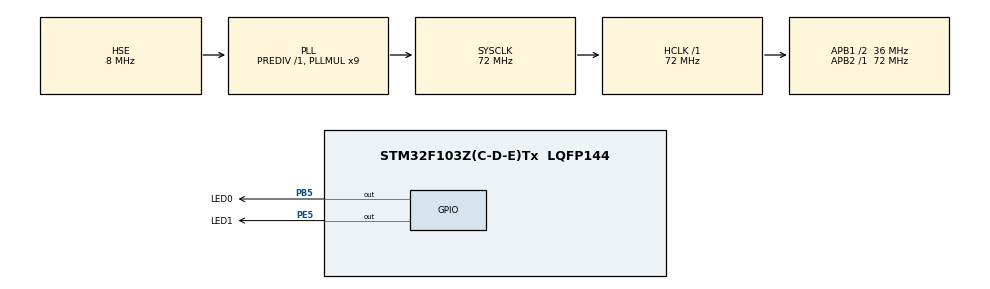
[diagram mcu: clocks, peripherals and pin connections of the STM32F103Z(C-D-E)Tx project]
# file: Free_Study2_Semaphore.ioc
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FREERTOS.BinarySemaphores01=bSem01,Dynamic,NULL
FREERTOS.CountingSemaphores01=cSem01,10,Dynamic,NULL
FREERTOS.Tasks01=Periodic,0,128,PeriodicTask,Default,NULL,Dynamic,NULL,NULL;Handle,0,128,HandleTask,Default,NULL,Dynamic,NULL,NULL;SemGen,0,128,SemGenTask,Default,NULL,Dynamic,NULL,NULL
FREERTOS.configUSE_COUNTING_SEMAPHORES=1
Mcu.Family=STM32F1
Mcu.Name=STM32F103Z(C-D-E)Tx
Mcu.Package=LQFP144
NVIC.PriorityGroup=NVIC_PRIORITYGROUP_4
NVIC.TIM4_IRQn=true\:0\:0\:false\:false\:true\:false\:false\:true
NVIC.TimeBase=TIM4_IRQn
NVIC.TimeBaseIP=TIM4
OSC_IN.Mode=HSE-External-Oscillator
OSC_IN.Signal=RCC_OSC_IN
OSC_OUT.Mode=HSE-External-Oscillator
OSC_OUT.Signal=RCC_OSC_OUT
PA13.Mode=Serial_Wire
PA13.Signal=SYS_JTMS-SWDIO
PA14.Mode=Serial_Wire
PA14.Signal=SYS_JTCK-SWCLK
PB5.GPIO_Label=LED0
PB5.Signal=GPIO_Output
PE5.GPIO_Label=LED1
PE5.Signal=GPIO_Output
ProjectManager.HeapSize=0x200
ProjectManager.StackSize=0x400
ProjectManager.TargetToolchain=STM32CubeIDE
RCC.AHBFreq_Value=72000000
RCC.APB1CLKDivider=RCC_HCLK_DIV2
RCC.APB1Freq_Value=36000000
RCC.APB1TimFreq_Value=72000000
RCC.APB2Freq_Value=72000000
RCC.APB2TimFreq_Value=72000000
RCC.HCLKFreq_Value=72000000
RCC.PLLMUL=RCC_PLL_MUL9
RCC.PLLSourceVirtual=RCC_PLLSOURCE_HSE
RCC.SYSCLKFreq_VALUE=72000000
RCC.SYSCLKSource=RCC_SYSCLKSOURCE_PLLCLK
RCC.USBFreq_Value=72000000
VP_FREERTOS_VS_CMSIS_V1.Mode=CMSIS_V1
VP_SYS_VS_tim4.Mode=TIM4
board=custom

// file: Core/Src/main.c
/* USER CODE BEGIN Header */
/**
 ******************************************************************************
 * @file           : main.c
 * @brief          : Main program body
 ******************************************************************************
 * @attention
 *
 * <h2><center>&copy; Copyright (c) 2020 STMicroelectronics.
 * All rights reserved.</center></h2>
 *
 * This software component is licensed by ST under BSD 3-Clause license,
 * the "License"; You may not use this file except in compliance with the
 * License. You may obtain a copy of the License at:
 *                        opensource.org/licenses/BSD-3-Clause
 *
 ******************************************************************************
 */
/* USER CODE END Header */
#include "main.h"
#include "cmsis_os.h"

osThreadId PeriodicHandle;
osThreadId HandleHandle;
osThreadId SemGenHandle;
osSemaphoreId bSem01Handle;
osSemaphoreId cSem01Handle;

void SystemClock_Config(void);
static void MX_GPIO_Init(void);
void PeriodicTask(const void *argument);
void HandleTask(const void *argument);
void SemGenTask(const void *argument);

int main(void)
{

	/* MCU Configuration--------------------------------------------------------*/

	/* Reset of all peripherals, Initializes the Flash interface and the Systick. */
	HAL_Init();

	/* Configure the system clock */
	SystemClock_Config();

	/* Initialize all configured peripherals */
	MX_GPIO_Init();

	/* Create the semaphores(s) */
	/* definition and creation of bSem01 */
	osSemaphoreDef(bSem01);
	bSem01Handle = osSemaphoreCreate(osSemaphore(bSem01), 1);

	/* definition and creation of cSem01 */
	osSemaphoreDef(cSem01);
	cSem01Handle = osSemaphoreCreate(osSemaphore(cSem01), 10);

	/* Create the thread(s) */
	/* definition and creation of Periodic */
	osThreadDef(Periodic, PeriodicTask, osPriorityNormal, 0, 128);
	PeriodicHandle = osThreadCreate(osThread(Periodic), NULL);

	/* definition and creation of Handle */
	osThreadDef(Handle, HandleTask, osPriorityNormal, 0, 128);
	HandleHandle = osThreadCreate(osThread(Handle), NULL);

	/* definition and creation of SemGen */
	osThreadDef(SemGen, SemGenTask, osPriorityNormal, 0, 128);
	SemGenHandle = osThreadCreate(osThread(SemGen), NULL);

	/* Start scheduler */
	osKernelStart();

	/* We should never get here as control is now taken by the scheduler */
	/* Infinite loop */
	while (1)
	{

	}
}

void SystemClock_Config(void)
{
	RCC_OscInitTypeDef RCC_OscInitStruct =
	{ 0 };
	RCC_ClkInitTypeDef RCC_ClkInitStruct =
	{ 0 };

	/** Initializes the RCC Oscillators according to the specified parameters
	 * in the RCC_OscInitTypeDef structure.
	 */
	RCC_OscInitStruct.OscillatorType = RCC_OSCILLATORTYPE_HSE;
	RCC_OscInitStruct.HSEState = RCC_HSE_ON;
	RCC_OscInitStruct.HSEPredivValue = RCC_HSE_PREDIV_DIV1;
	RCC_OscInitStruct.HSIState = RCC_HSI_ON;
	RCC_OscInitStruct.PLL.PLLState = RCC_PLL_ON;
	RCC_OscInitStruct.PLL.PLLSource = RCC_PLLSOURCE_HSE;
	RCC_OscInitStruct.PLL.PLLMUL = RCC_PLL_MUL9;
	if (HAL_RCC_OscConfig(&RCC_OscInitStruct) != HAL_OK)
	{
		Error_Handler();
	}
	/** Initializes the CPU, AHB and APB buses clocks
	 */
	RCC_ClkInitStruct.ClockType = RCC_CLOCKTYPE_HCLK | RCC_CLOCKTYPE_SYSCLK
			| RCC_CLOCKTYPE_PCLK1 | RCC_CLOCKTYPE_PCLK2;
	RCC_ClkInitStruct.SYSCLKSource = RCC_SYSCLKSOURCE_PLLCLK;
	RCC_ClkInitStruct.AHBCLKDivider = RCC_SYSCLK_DIV1;
	RCC_ClkInitStruct.APB1CLKDivider = RCC_HCLK_DIV2;
	RCC_ClkInitStruct.APB2CLKDivider = RCC_HCLK_DIV1;

	if (HAL_RCC_ClockConfig(&RCC_ClkInitStruct, FLASH_LATENCY_2) != HAL_OK)
	{
		Error_Handler();
	}
}

static void MX_GPIO_Init(void)
{
	GPIO_InitTypeDef GPIO_InitStruct =
	{ 0 };

	/* GPIO Ports Clock Enable */
	__HAL_RCC_GPIOE_CLK_ENABLE();
	__HAL_RCC_GPIOA_CLK_ENABLE();
	__HAL_RCC_GPIOB_CLK_ENABLE();

	/*Configure GPIO pin Output Level */
	HAL_GPIO_WritePin(LED1_GPIO_Port, LED1_Pin, GPIO_PIN_RESET);

	/*Configure GPIO pin Output Level */
	HAL_GPIO_WritePin(LED0_GPIO_Port, LED0_Pin, GPIO_PIN_RESET);

	/*Configure GPIO pin : LED1_Pin */
	GPIO_InitStruct.Pin = LED1_Pin;
	GPIO_InitStruct.Mode = GPIO_MODE_OUTPUT_PP;
	GPIO_InitStruct.Pull = GPIO_NOPULL;
	GPIO_InitStruct.Speed = GPIO_SPEED_FREQ_LOW;
	HAL_GPIO_Init(LED1_GPIO_Port, &GPIO_InitStruct);

	/*Configure GPIO pin : LED0_Pin */
	GPIO_InitStruct.Pin = LED0_Pin;
	GPIO_InitStruct.Mode = GPIO_MODE_OUTPUT_PP;
	GPIO_InitStruct.Pull = GPIO_NOPULL;
	GPIO_InitStruct.Speed = GPIO_SPEED_FREQ_LOW;
	HAL_GPIO_Init(LED0_GPIO_Port, &GPIO_InitStruct);

}

void PeriodicTask(const void *argument)
{
	/* USER CODE BEGIN 5 */
	/* Infinite loop */
	for (;;)
	{
//    osDelay(500);
//    HAL_GPIO_TogglePin(LED0_GPIO_Port, LED0_Pin);
//    osDelay(500);
//    HAL_GPIO_TogglePin(LED0_GPIO_Port, LED0_Pin);
//
//    osSemaphoreRelease(bSem01Handle);//释放（发送）信号�?
	}
	/* USER CODE END 5 */
}

void HandleTask(const void *argument)
{
	/* USER CODE BEGIN HandleTask */
	/* Infinite loop */
	for (;;)
	{
		osSemaphoreWait(cSem01Handle, osWaitForever); //等待信号释放
		HAL_GPIO_TogglePin(LED0_GPIO_Port, LED0_Pin);
		HAL_GPIO_TogglePin(LED1_GPIO_Port, LED1_Pin);
		HAL_Delay(500);

		HAL_GPIO_TogglePin(LED0_GPIO_Port, LED0_Pin);
		HAL_GPIO_TogglePin(LED1_GPIO_Port, LED1_Pin);
		HAL_Delay(500);

	}
	/* USER CODE END HandleTask */
}

void SemGenTask(const void *argument)
{
	/* USER CODE BEGIN SemGenTask */
	/* Infinite loop */
	for (;;)
	{
		osDelay(1000);
		osSemaphoreRelease(cSem01Handle); //释放一次信号量
		osDelay(1000);
		osSemaphoreRelease(cSem01Handle); //释放一次信号量
		osSemaphoreRelease(cSem01Handle); //释放一次信号量
		osDelay(1000);
		osSemaphoreRelease(cSem01Handle); //释放一次信号量
		osSemaphoreRelease(cSem01Handle); //释放一次信号量
		osSemaphoreRelease(cSem01Handle); //释放一次信号量
		osDelay(2000);

	}
	/* USER CODE END SemGenTask */
}

void HAL_TIM_PeriodElapsedCallback(TIM_HandleTypeDef *htim)
{
	if (htim->Instance == TIM4)
	{
		HAL_IncTick();
	}
}

void Error_Handler(void)
{
}

/************************ (C) COPYRIGHT STMicroelectronics *****END OF FILE****/
